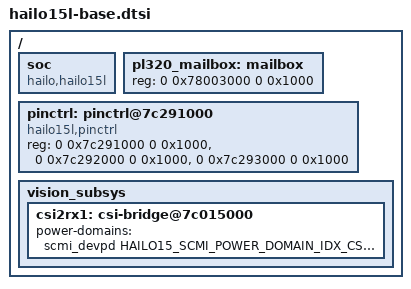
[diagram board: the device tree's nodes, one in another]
// SPDX-License-Identifier:     GPL-2.0
/*
 * Copyright (c) 2019-2024 Hailo Technologies Ltd. All rights reserved.
 */

#define HAILO_SOC_TYPE HAILO_SOC_HAILO15L
#include "hailo15-family-base.dtsi"

/ {
    soc {
        compatible = "hailo,hailo15l";
    };

    pl320_mailbox: mailbox {
        reg = <0 0x78003000 0 0x1000>;
    };

    pinctrl: pinctrl@7c291000 {
        compatible = "hailo15l,pinctrl";
        reg = <0 0x7c291000 0 0x1000>,
                <0 0x7c292000 0 0x1000>,
                <0 0x7c293000 0 0x1000>;
        reg-names = "general_pads_config_base", "gpio_pads_config_base", "slow_pads_config_base";
    };

    vision_subsys: vision_subsys {
        csi2rx1: csi-bridge@7c015000 {
            power-domains = <&scmi_devpd HAILO15_SCMI_POWER_DOMAIN_IDX_CSI_RX0>;
        };
    };
};
